VERSION "created by canmatrix"

NS_ :

BS_:

BU_: User ADM_PC_LL25 ADM_PC_BC25 ADM_PC_BP25 ADM_PC_BI25

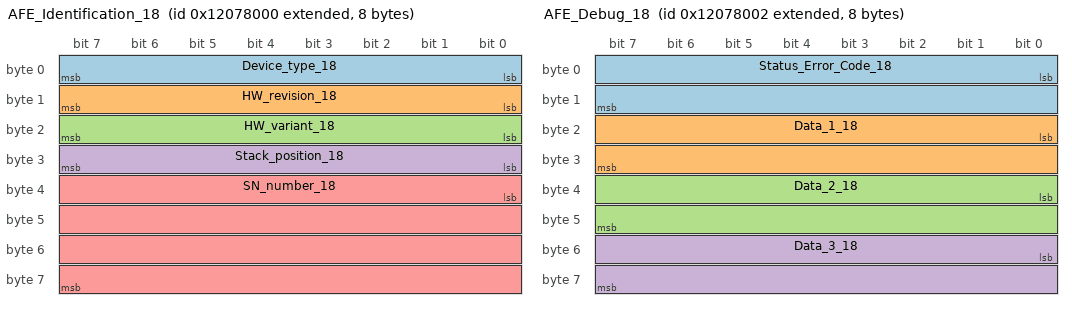
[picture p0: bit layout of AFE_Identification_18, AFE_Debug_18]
BO_ 2449965056 AFE_Identification_18: 8 ADM_PC_BP25
 SG_ Device_type_18 : 0|8@1+ (1,0) [0|255] "" Vector__XXX
 SG_ HW_revision_18 : 8|8@1+ (1,0) [0|255] "" Vector__XXX
 SG_ HW_variant_18 : 16|8@1+ (1,0) [0|255] "" Vector__XXX
 SG_ Stack_position_18 : 24|8@1+ (1,0) [0|255] "" Vector__XXX
 SG_ SN_number_18 : 32|32@1+ (1,0) [0|4294967295] "" Vector__XXX

BO_ 2449965057 AFE_FwInfo_18: 8 ADM_PC_BP25
 SG_ FW_info_mux_18 M : 56|8@1+ (1,0) [0|255] "" Vector__XXX
 SG_ FW_revision_0_18 m0 : 0|8@1+ (1,0) [0|255] "" Vector__XXX
 SG_ FW_revision_1_18 m0 : 8|8@1+ (1,0) [0|255] "" Vector__XXX
 SG_ FW_revision_2_18 m0 : 16|8@1+ (1,0) [0|255] "" Vector__XXX
 SG_ FW_revision_3_18 m0 : 24|8@1+ (1,0) [0|255] "" Vector__XXX
 SG_ FW_revision_4_18 m0 : 32|8@1+ (1,0) [0|255] "" Vector__XXX
 SG_ FW_revision_5_18 m0 : 40|8@1+ (1,0) [0|255] "" Vector__XXX
 SG_ FW_revision_6_18 m0 : 48|8@1+ (1,0) [0|255] "" Vector__XXX
 SG_ FW_revision_7_18 m1 : 0|8@1+ (1,0) [0|255] "" Vector__XXX
 SG_ FW_revision_8_18 m1 : 8|8@1+ (1,0) [0|255] "" Vector__XXX
 SG_ FW_revision_9_18 m1 : 16|8@1+ (1,0) [0|255] "" Vector__XXX
 SG_ FW_revision_10_18 m1 : 24|8@1+ (1,0) [0|255] "" Vector__XXX
 SG_ FW_revision_11_18 m1 : 32|8@1+ (1,0) [0|255] "" Vector__XXX
 SG_ FW_revision_12_18 m1 : 40|8@1+ (1,0) [0|255] "" Vector__XXX
 SG_ FW_revision_13_18 m1 : 48|8@1+ (1,0) [0|255] "" Vector__XXX
 SG_ FW_datecode_0_18 m2 : 0|8@1+ (1,0) [0|255] "" Vector__XXX
 SG_ FW_datecode_1_18 m2 : 8|8@1+ (1,0) [0|255] "" Vector__XXX
 SG_ FW_datecode_2_18 m2 : 16|8@1+ (1,0) [0|255] "" Vector__XXX
 SG_ FW_datecode_3_18 m2 : 24|8@1+ (1,0) [0|255] "" Vector__XXX
 SG_ FW_datecode_4_18 m2 : 32|8@1+ (1,0) [0|255] "" Vector__XXX
 SG_ FW_datecode_5_18 m2 : 40|8@1+ (1,0) [0|255] "" Vector__XXX
 SG_ FW_datecode_6_18 m2 : 48|8@1+ (1,0) [0|255] "" Vector__XXX
 SG_ FW_datecode_7_18 m3 : 0|8@1+ (1,0) [0|255] "" Vector__XXX
 SG_ FW_datecode_8_18 m3 : 8|8@1+ (1,0) [0|255] "" Vector__XXX
 SG_ FW_datecode_9_18 m3 : 16|8@1+ (1,0) [0|255] "" Vector__XXX
 SG_ FW_datecode_10_18 m3 : 24|8@1+ (1,0) [0|255] "" Vector__XXX
 SG_ FW_datecode_11_18 m3 : 32|8@1+ (1,0) [0|255] "" Vector__XXX
 SG_ FW_datecode_12_18 m3 : 40|8@1+ (1,0) [0|255] "" Vector__XXX
 SG_ FW_datecode_13_18 m3 : 48|8@1+ (1,0) [0|255] "" Vector__XXX

BO_ 2449965069 _AFE_Boot_FwInfo_18: 8 ADM_PC_BP25
 SG_ Boot_FW_info_mux_18 M : 56|8@1+ (1,0) [0|255] "" Vector__XXX
 SG_ FW_revision_0_18 m0 : 0|8@1+ (1,0) [0|255] "" Vector__XXX
 SG_ FW_revision_1_18 m0 : 8|8@1+ (1,0) [0|255] "" Vector__XXX
 SG_ FW_revision_2_18 m0 : 16|8@1+ (1,0) [0|255] "" Vector__XXX
 SG_ FW_revision_3_18 m0 : 24|8@1+ (1,0) [0|255] "" Vector__XXX
 SG_ FW_revision_4_18 m0 : 32|8@1+ (1,0) [0|255] "" Vector__XXX
 SG_ FW_revision_5_18 m0 : 40|8@1+ (1,0) [0|255] "" Vector__XXX
 SG_ FW_revision_6_18 m0 : 48|8@1+ (1,0) [0|255] "" Vector__XXX
 SG_ FW_revision_7_18 m1 : 0|8@1+ (1,0) [0|255] "" Vector__XXX
 SG_ FW_revision_8_18 m1 : 8|8@1+ (1,0) [0|255] "" Vector__XXX
 SG_ FW_revision_9_18 m1 : 16|8@1+ (1,0) [0|255] "" Vector__XXX
 SG_ FW_revision_10_18 m1 : 24|8@1+ (1,0) [0|255] "" Vector__XXX
 SG_ FW_revision_11_18 m1 : 32|8@1+ (1,0) [0|255] "" Vector__XXX
 SG_ FW_revision_12_18 m1 : 40|8@1+ (1,0) [0|255] "" Vector__XXX
 SG_ FW_revision_13_18 m1 : 48|8@1+ (1,0) [0|255] "" Vector__XXX
 SG_ FW_datecode_0_18 m2 : 0|8@1+ (1,0) [0|255] "" Vector__XXX
 SG_ FW_datecode_1_18 m2 : 8|8@1+ (1,0) [0|255] "" Vector__XXX
 SG_ FW_datecode_2_18 m2 : 16|8@1+ (1,0) [0|255] "" Vector__XXX
 SG_ FW_datecode_3_18 m2 : 24|8@1+ (1,0) [0|255] "" Vector__XXX
 SG_ FW_datecode_4_18 m2 : 32|8@1+ (1,0) [0|255] "" Vector__XXX
 SG_ FW_datecode_5_18 m2 : 40|8@1+ (1,0) [0|255] "" Vector__XXX
 SG_ FW_datecode_6_18 m2 : 48|8@1+ (1,0) [0|255] "" Vector__XXX
 SG_ FW_datecode_7_18 m3 : 0|8@1+ (1,0) [0|255] "" Vector__XXX
 SG_ FW_datecode_8_18 m3 : 8|8@1+ (1,0) [0|255] "" Vector__XXX
 SG_ FW_datecode_9_18 m3 : 16|8@1+ (1,0) [0|255] "" Vector__XXX
 SG_ FW_datecode_10_18 m3 : 24|8@1+ (1,0) [0|255] "" Vector__XXX
 SG_ FW_datecode_11_18 m3 : 32|8@1+ (1,0) [0|255] "" Vector__XXX
 SG_ FW_datecode_12_18 m3 : 40|8@1+ (1,0) [0|255] "" Vector__XXX
 SG_ FW_datecode_13_18 m3 : 48|8@1+ (1,0) [0|255] "" Vector__XXX

BO_ 2449965058 AFE_Debug_18: 8 ADM_PC_BP25
 SG_ Status_Error_Code_18 : 0|16@1+ (1,0) [0|65535] "" Vector__XXX
 SG_ Data_1_18 : 16|16@1+ (1,0) [0|65535] "" Vector__XXX
 SG_ Data_2_18 : 32|16@1+ (1,0) [0|65535] "" Vector__XXX
 SG_ Data_3_18 : 48|16@1+ (1,0) [0|65535] "" Vector__XXX

BO_ 2449965063 AFE_Status_18: 8 ADM_PC_BP25
 SG_ Running_18 : 0|1@1+ (1,0) [0|1] "" Vector__XXX
 SG_ PWM_18 : 1|1@1+ (1,0) [0|1] "" Vector__XXX
 SG_ Current_dc_loop_mode_18 : 2|1@1+ (1,0) [0|1] "" Vector__XXX
 SG_ Current_ac_loop_mode_18 : 3|1@1+ (1,0) [0|1] "" Vector__XXX
 SG_ Buck_18 : 5|1@1+ (1,0) [0|1] "" Vector__XXX
 SG_ Boost_18 : 6|1@1+ (1,0) [0|1] "" Vector__XXX
 SG_ Precharge_dc_buck_mode_18 : 7|1@1+ (1,0) [0|1] "" Vector__XXX
 SG_ Precharge_dc_boost_mode_18 : 8|1@1+ (1,0) [0|1] "" Vector__XXX
 SG_ Rectifier_3ph_18 : 9|1@1+ (1,0) [0|1] "" Vector__XXX
 SG_ Stack_mode_18 : 10|1@1+ (1,0) [0|1] "" Vector__XXX
 SG_ Master_18 : 11|1@1+ (1,0) [0|1] "" Vector__XXX
 SG_ Slave_18 : 12|1@1+ (1,0) [0|1] "" Vector__XXX
 SG_ Inverter_1ph_18 : 13|1@1+ (1,0) [0|1] "" Vector__XXX
 SG_ Boost_Neutral_18 : 14|1@1+ (1,0) [0|1] "" Vector__XXX
 SG_ Rectifier_1ph_18 : 15|1@1+ (1,0) [0|1] "" Vector__XXX
 SG_ Inverter_3ph_18 : 16|1@1+ (1,0) [0|1] "" Vector__XXX
 SG_ Ready_18 : 17|1@1+ (1,0) [0|1] "" Vector__XXX
 SG_ Inverter_1ph_Sync_18 : 18|1@1+ (1,0) [0|1] "" Vector__XXX
 SG_ Neutral_18 : 19|1@1+ (1,0) [0|1] "" Vector__XXX
 SG_ Rectifier_1ph_Buck_18 : 20|1@1+ (1,0) [0|1] "" Vector__XXX
 SG_ Inverter_1ph_Boost_18 : 21|1@1+ (1,0) [0|1] "" Vector__XXX
 SG_ Rectifier_distributed_18 : 22|1@1+ (1,0) [0|1] "" Vector__XXX
 SG_ MPPT_buck_18 : 23|1@1+ (1,0) [0|1] "" Vector__XXX
 SG_ MPPT_boost_18 : 24|1@1+ (1,0) [0|1] "" Vector__XXX
 SG_ Buck_2p_float_18 : 25|1@1+ (1,0) [0|1] "" Vector__XXX
 SG_ Inverter_1ph_Distributed_18 : 26|1@1+ (1,0) [0|1] "" Vector__XXX

BO_ 2449965062 AFE_Faults_18: 3 ADM_PC_BP25
 SG_ Protection_trip_internal_18 : 0|1@1+ (1,0) [0|1] "" Vector__XXX
 SG_ Protection_trip_external_18 : 1|1@1+ (1,0) [0|1] "" Vector__XXX
 SG_ Phase_U_overcurrent_18 : 2|1@1+ (1,0) [0|1] "" Vector__XXX
 SG_ Phase_U_overvoltage_18 : 3|1@1+ (1,0) [0|1] "" Vector__XXX
 SG_ Phase_U_undervoltage_18 : 4|1@1+ (1,0) [0|1] "" Vector__XXX
 SG_ Phase_V_overvoltage_18 : 5|1@1+ (1,0) [0|1] "" Vector__XXX
 SG_ Phase_V_undervoltage_18 : 6|1@1+ (1,0) [0|1] "" Vector__XXX
 SG_ Phase_V_overcurrent_18 : 7|1@1+ (1,0) [0|1] "" Vector__XXX
 SG_ Phase_W_overvoltage_18 : 8|1@1+ (1,0) [0|1] "" Vector__XXX
 SG_ Phase_W_undervoltage_18 : 9|1@1+ (1,0) [0|1] "" Vector__XXX
 SG_ Phase_W_overcurrent_18 : 10|1@1+ (1,0) [0|1] "" Vector__XXX
 SG_ DC_undervoltage_18 : 11|1@1+ (1,0) [0|1] "" Vector__XXX
 SG_ DC_overvoltage_18 : 12|1@1+ (1,0) [0|1] "" Vector__XXX
 SG_ MOSFET_overtemperature_18 : 13|1@1+ (1,0) [0|1] "" Vector__XXX
 SG_ Inductor_overtemperature_18 : 14|1@1+ (1,0) [0|1] "" Vector__XXX
 SG_ Keep_Alive_not_served_18 : 15|1@1+ (1,0) [0|1] "" Vector__XXX
 SG_ PLL_not_locked_18 : 16|1@1+ (1,0) [0|1] "" Vector__XXX
 SG_ NFO_18 : 20|1@1+ (1,0) [0|1] "" Vector__XXX
 SG_ Measurement_system_failure_18 : 21|1@1+ (1,0) [0|1] "" Vector__XXX
 SG_ EEPROM_failure_18 : 22|1@1+ (1,0) [0|1] "" Vector__XXX
 SG_ System_18 : 23|1@1+ (1,0) [0|1] "" Vector__XXX

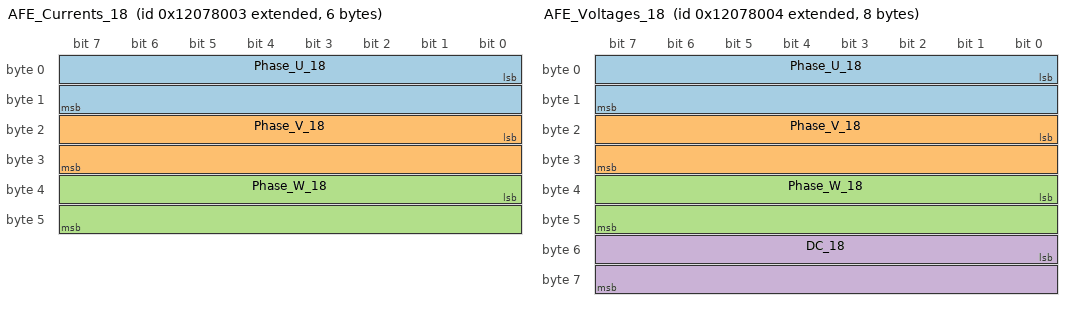
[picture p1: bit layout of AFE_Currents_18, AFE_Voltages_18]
BO_ 2449965059 AFE_Currents_18: 6 ADM_PC_BP25
 SG_ Phase_U_18 : 0|16@1- (0.01,0) [-327.68|327.67] "A" Vector__XXX
 SG_ Phase_V_18 : 16|16@1- (0.01,0) [-327.68|327.67] "A" Vector__XXX
 SG_ Phase_W_18 : 32|16@1- (0.01,0) [-327.68|327.67] "A" Vector__XXX

BO_ 2449965072 AFE_DC_Bus_current_18: 2 ADM_PC_BP25
 SG_ Bus_current_18 : 0|16@1- (0.01,0) [-327.68|327.67] "A" Vector__XXX

BO_ 2449965070 _AFE_Broadcast_18: 8 ADM_PC_BP25
 SG_ Diagnostics_Index_18 M : 56|8@1+ (1,0) [0|255] "" Vector__XXX
 SG_ Phase_U_18 m1 : 8|16@1- (0.01,0) [-327.68|327.67] "A" ADM_PC_BP25
 SG_ Phase_V_18 m1 : 24|16@1- (0.01,0) [-327.68|327.67] "A" ADM_PC_BP25
 SG_ Phase_W_18 m1 : 40|16@1- (0.01,0) [-327.68|327.67] "A" ADM_PC_BP25
 SG_ Stack_position_18 : 0|5@1+ (1,0) [0|31] "" ADM_PC_BP25
 SG_ Group_ID_18 : 5|3@1+ (1,0) [0|7] "" ADM_PC_BP25

BO_ 2449965060 AFE_Voltages_18: 8 ADM_PC_BP25
 SG_ Phase_U_18 : 0|16@1- (0.1,0) [-3276.8|3276.7] "V" Vector__XXX
 SG_ Phase_V_18 : 16|16@1- (0.1,0) [-3276.8|3276.7] "V" Vector__XXX
 SG_ Phase_W_18 : 32|16@1- (0.1,0) [-3276.8|3276.7] "V" Vector__XXX
 SG_ DC_18 : 48|16@1- (0.1,0) [-3276.8|3276.7] "V" Vector__XXX

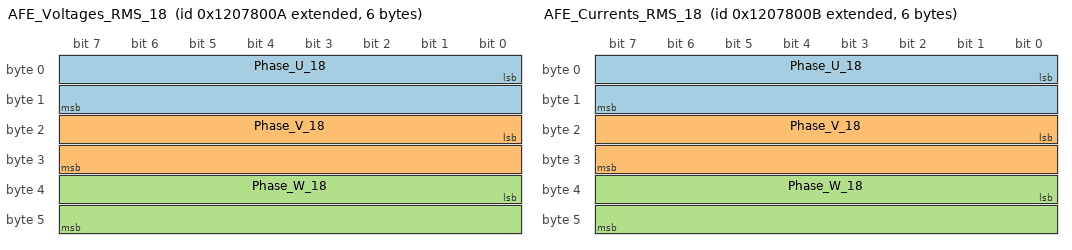
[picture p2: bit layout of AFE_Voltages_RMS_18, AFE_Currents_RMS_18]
BO_ 2449965066 AFE_Voltages_RMS_18: 6 ADM_PC_BP25
 SG_ Phase_U_18 : 0|16@1+ (0.1,0) [0|6553.5] "V" Vector__XXX
 SG_ Phase_V_18 : 16|16@1+ (0.1,0) [0|6553.5] "V" Vector__XXX
 SG_ Phase_W_18 : 32|16@1+ (0.1,0) [0|6553.5] "V" Vector__XXX

BO_ 2449965067 AFE_Currents_RMS_18: 6 ADM_PC_BP25
 SG_ Phase_U_18 : 0|16@1+ (0.01,0) [0.00|655.35] "A" Vector__XXX
 SG_ Phase_V_18 : 16|16@1+ (0.01,0) [0.00|655.35] "A" Vector__XXX
 SG_ Phase_W_18 : 32|16@1+ (0.01,0) [0.00|655.35] "A" Vector__XXX

BO_ 2449965068 AFE_Mains_18: 4 ADM_PC_BP25
 SG_ Frequency_18 : 0|16@1+ (0.01,0) [0.00|655.35] "Hz" Vector__XXX
 SG_ Phase_18 : 16|16@1- (0.1,0) [-3276.8|3276.7] "Deg." Vector__XXX

BO_ 2449965061 AFE_Temperatures_18: 4 ADM_PC_BP25
 SG_ Temp_Bridge_18 : 0|16@1- (0.01,0) [-327.68|327.67] "°C" Vector__XXX
 SG_ Temp_Inductors_18 : 16|16@1- (0.01,0) [-327.68|327.67] "°C" Vector__XXX

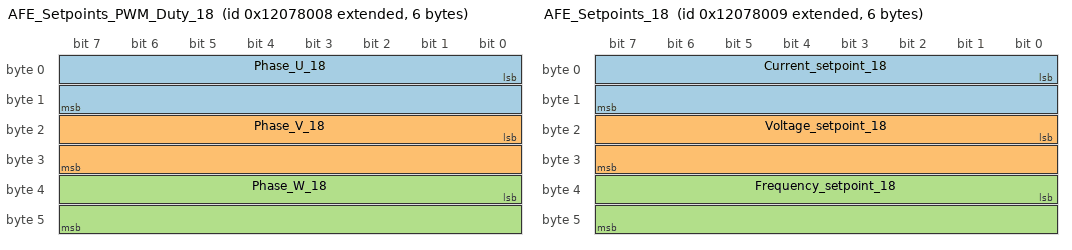
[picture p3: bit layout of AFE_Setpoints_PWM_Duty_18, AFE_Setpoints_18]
BO_ 2449965064 AFE_Setpoints_PWM_Duty_18: 6 ADM_PC_BP25
 SG_ Phase_U_18 : 0|16@1+ (0.001525902,0) [0E-009|99.999987570] "%" Vector__XXX
 SG_ Phase_V_18 : 16|16@1+ (0.001525902,0) [0E-009|99.999987570] "%" Vector__XXX
 SG_ Phase_W_18 : 32|16@1+ (0.001525902,0) [0E-009|99.999987570] "%" Vector__XXX

BO_ 2449965065 AFE_Setpoints_18: 6 ADM_PC_BP25
 SG_ Current_setpoint_18 : 0|16@1- (0.01,0) [-327.68|327.67] "A" Vector__XXX
 SG_ Voltage_setpoint_18 : 16|16@1+ (0.1,0) [0|6553.5] "V" Vector__XXX
 SG_ Frequency_setpoint_18 : 32|16@1+ (0.01,0) [0.00|655.35] "Hz" Vector__XXX

BO_ 2449932384 AFE_Keep_Alive_18: 1 User
 SG_ Keep_Alive_Enable_18 : 0|1@1+ (1,0) [0|1] "" ADM_PC_BP25

BO_ 2449932352 AFE_Mode_Control_18: 8 User
 SG_ Converter_ON_18 : 0|1@1+ (1,0) [0|1] "" ADM_PC_BP25
 SG_ PWM_ON_18 : 1|1@1+ (1,0) [0|1] "" ADM_PC_BP25
 SG_ DC_Current_feedback_ON_18 : 2|1@1+ (1,0) [0|1] "" ADM_PC_BP25
 SG_ AC_Current_feedback_ON_18 : 3|1@1+ (1,0) [0|1] "" ADM_PC_BP25
 SG_ Buck_ON_18 : 5|1@1+ (1,0) [0|1] "" ADM_PC_BP25
 SG_ Boost_ON_18 : 6|1@1+ (1,0) [0|1] "" ADM_PC_BP25
 SG_ Rectifier_3ph_ON_18 : 9|1@1+ (1,0) [0|1] "" ADM_PC_BP25
 SG_ Inverter_1ph_ON_18 : 10|1@1+ (1,0) [0|1] "" ADM_PC_BP25
 SG_ Rectifier_1ph_ON_18 : 11|1@1+ (1,0) [0|1] "" ADM_PC_BP25
 SG_ Boost_Neutral_ON_18 : 12|1@1+ (1,0) [0|1] "" ADM_PC_BP25
 SG_ Inverter_3ph_ON_18 : 13|1@1+ (1,0) [0|1] "" ADM_PC_BP25
 SG_ Inverter_1ph_Sync_ON_18 : 14|1@1+ (1,0) [0|1] "" ADM_PC_BP25
 SG_ Neutral_ON_18 : 15|1@1+ (1,0) [0|1] "" ADM_PC_BP25
 SG_ Rectifier_1ph_Buck_ON_18 : 16|1@1+ (1,0) [0|1] "" ADM_PC_BP25
 SG_ Inverter_1ph_Boost_ON_18 : 17|1@1+ (1,0) [0|1] "" ADM_PC_BP25
 SG_ Rectifier_Distributed_ON_18 : 18|1@1+ (1,0) [0|1] "" ADM_PC_BP25
 SG_ MPPT_buck_ON_18 : 19|1@1+ (1,0) [0|1] "" ADM_PC_BP25
 SG_ MPPT_boost_ON_18 : 20|1@1+ (1,0) [0|1] "" ADM_PC_BP25
 SG_ Buck_2p_float_ON_18 : 21|1@1+ (1,0) [0|1] "" ADM_PC_BP25
 SG_ Inverter_1ph_Distributed_ON_18 : 22|1@1+ (1,0) [0|1] "" ADM_PC_BP25

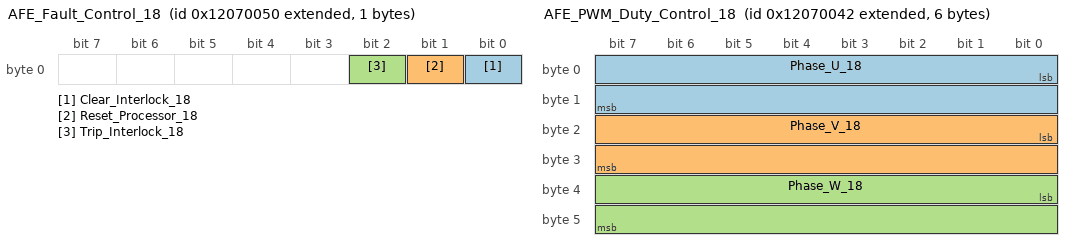
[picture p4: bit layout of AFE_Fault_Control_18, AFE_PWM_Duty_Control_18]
BO_ 2449932368 AFE_Fault_Control_18: 1 User
 SG_ Clear_Interlock_18 : 0|1@1+ (1,0) [0|1] "" ADM_PC_BP25
 SG_ Reset_Processor_18 : 1|1@1+ (1,0) [0|1] "" ADM_PC_BP25
 SG_ Trip_Interlock_18 : 2|1@1+ (1,0) [0|1] "" ADM_PC_BP25

BO_ 2449932353 AFE_Reactive_Current_Setpoint_Co: 2 User
 SG_ Reactive_current_setpoint_18 : 0|16@1- (0.01,0) [-150|150] "A" ADM_PC_BP25

BO_ 2449932354 AFE_PWM_Duty_Control_18: 6 User
 SG_ Phase_U_18 : 0|16@1+ (0.001525902,0) [0E-009|99.999987570] "%" ADM_PC_BP25
 SG_ Phase_V_18 : 16|16@1+ (0.001525902,0) [0E-009|99.999987570] "%" ADM_PC_BP25
 SG_ Phase_W_18 : 32|16@1+ (0.001525902,0) [0E-009|99.999987570] "%" ADM_PC_BP25

BO_ 2449932355 AFE_Current_Setpoint_Control_18: 2 User
 SG_ Current_setpoint_18 : 0|16@1- (0.01,0) [-150|150] "A" ADM_PC_BP25

BO_ 2449932356 AFE_Voltage_Setpoint_Control_18: 2 User
 SG_ Voltage_setpoint_18 : 0|16@1+ (0.1,0) [0|1500] "V" ADM_PC_BP25

BO_ 2449932360 AFE_Frequency_Setpoint_Control_1: 2 User
 SG_ Frequency_setpoint_18 : 0|16@1+ (0.01,0) [40|70] "Hz" ADM_PC_BP25

BO_ 2449932361 AFE_Phase_Setpoint_Control_18: 2 User
 SG_ Phase_setpoint_18 : 0|16@1+ (1,0) [0|360] "deg" ADM_PC_BP25

BO_ 2449932400 AFE_Rectifier_Setpoint_Control_1: 8 User
 SG_ Voltage_setpoint_2_18 : 0|16@1+ (0.1,0) [0|1500] "V" ADM_PC_BP25
 SG_ Current_setpoint_2_18 : 16|16@1- (0.01,0) [-150|150] "A" ADM_PC_BP25

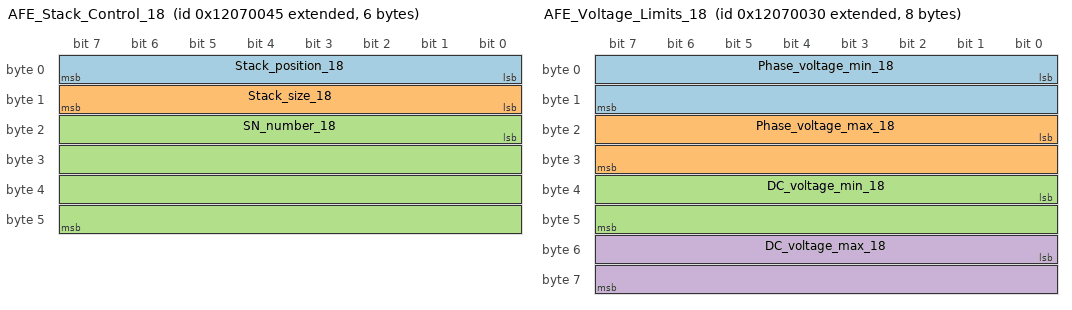
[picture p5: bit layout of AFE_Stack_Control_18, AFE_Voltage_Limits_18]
BO_ 2449932357 AFE_Stack_Control_18: 6 User
 SG_ Stack_position_18 : 0|8@1+ (1,0) [0|255] "" ADM_PC_BP25
 SG_ Stack_size_18 : 8|8@1+ (1,0) [0|255] "" ADM_PC_BP25
 SG_ SN_number_18 : 16|32@1+ (1,0) [0|4294967295] "" ADM_PC_BP25

BO_ 2449932336 AFE_Voltage_Limits_18: 8 User
 SG_ Phase_voltage_min_18 : 0|16@1- (0.1,0) [0|3276.7] "V" ADM_PC_BP25
 SG_ Phase_voltage_max_18 : 16|16@1- (0.1,0) [-3276.8|850] "V" ADM_PC_BP25
 SG_ DC_voltage_min_18 : 32|16@1- (0.1,0) [0|3276.7] "V" ADM_PC_BP25
 SG_ DC_voltage_max_18 : 48|16@1- (0.1,0) [-3276.8|850] "V" ADM_PC_BP25

BO_ 2449932337 AFE_Current_Limits_18: 4 User
 SG_ Phase_current_min_18 : 0|16@1- (0.01,0) [-60|60] "A" ADM_PC_BP25
 SG_ Phase_current_max_18 : 16|16@1- (0.01,0) [-60|60] "A" ADM_PC_BP25

BO_ 2449932364 AFE_Group_Control_18: 1 User
 SG_ Group_ID_18 : 0|8@1+ (1,0) [0|255] "" ADM_PC_BP25

BO_ 2449965071 AFE_Group_Info_18: 1 ADM_PC_BP25
 SG_ Group_ID_18 : 0|8@1+ (1,0) [0|255] "" Vector__XXX

BO_ 2449932385 AFE_System_Flags_Control_18: 8 User
 SG_ Factory_mode_18 : 0|1@1+ (1,0) [0|1] "" ADM_PC_BP25
 SG_ Silent_CAN_mode_18 : 1|1@1+ (1,0) [0|1] "" ADM_PC_BP25

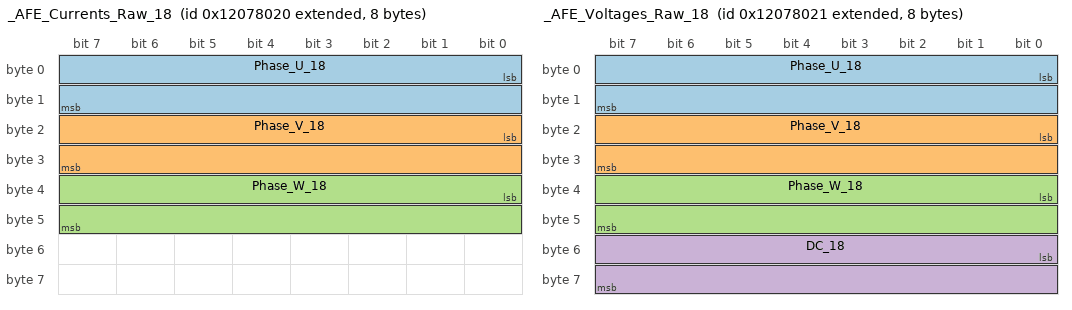
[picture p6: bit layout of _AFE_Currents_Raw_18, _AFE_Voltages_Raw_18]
BO_ 2449965088 _AFE_Currents_Raw_18: 8 ADM_PC_BP25
 SG_ Phase_U_18 : 0|16@1- (1,0) [-32768|32767] "" Vector__XXX
 SG_ Phase_V_18 : 16|16@1- (1,0) [-32768|32767] "" Vector__XXX
 SG_ Phase_W_18 : 32|16@1- (1,0) [-32768|32767] "" Vector__XXX

BO_ 2449965089 _AFE_Voltages_Raw_18: 8 ADM_PC_BP25
 SG_ Phase_U_18 : 0|16@1- (1,0) [-32768|32767] "" Vector__XXX
 SG_ Phase_V_18 : 16|16@1- (1,0) [-32768|32767] "" Vector__XXX
 SG_ Phase_W_18 : 32|16@1- (1,0) [-32768|32767] "" Vector__XXX
 SG_ DC_18 : 48|16@1- (1,0) [-32768|32767] "" Vector__XXX

BO_ 2449932362 _AFE_ADC_Calibration_Mode_18: 1 User
 SG_ Calibration_Index_18 M : 2|5@1+ (1,0) [0|31] "" Vector__XXX
 SG_ Current_U_18 m1 : 0|2@1+ (1,0) [0|3] "" ADM_PC_BP25
 SG_ Current_V_18 m2 : 0|2@1+ (1,0) [0|3] "" ADM_PC_BP25
 SG_ Current_W_18 m3 : 0|2@1+ (1,0) [0|3] "" ADM_PC_BP25
 SG_ Voltage_U_18 m4 : 0|2@1+ (1,0) [0|3] "" ADM_PC_BP25
 SG_ Voltage_V_18 m5 : 0|2@1+ (1,0) [0|3] "" ADM_PC_BP25
 SG_ Voltage_W_18 m6 : 0|2@1+ (1,0) [0|3] "" ADM_PC_BP25
 SG_ Voltage_DC_18 m7 : 0|2@1+ (1,0) [0|3] "" ADM_PC_BP25
 SG_ start_18 : 7|1@1+ (1,0) [0|1] "" ADM_PC_BP25

BO_ 2449932363 _AFE_ADC_Calibration_Setpoint_18: 3 User
 SG_ Calibration_Index_18 M : 16|5@1+ (1,0) [0|31] "" Vector__XXX
 SG_ Current_U_18 m1 : 0|16@1- (0.01,0) [-100|100] "A" ADM_PC_BP25
 SG_ Current_V_18 m2 : 0|16@1- (0.01,0) [-100|100] "A" ADM_PC_BP25
 SG_ Current_W_18 m3 : 0|16@1- (0.01,0) [-100|100] "A" ADM_PC_BP25
 SG_ Voltage_U_18 m4 : 0|16@1+ (0.1,0) [0|1500] "V" ADM_PC_BP25
 SG_ Voltage_V_18 m5 : 0|16@1+ (0.1,0) [0|1500] "V" ADM_PC_BP25
 SG_ Voltage_W_18 m6 : 0|16@1+ (0.1,0) [0|1500] "V" ADM_PC_BP25
 SG_ Voltage_DC_18 m7 : 0|16@1+ (0.1,0) [0|1500] "V" ADM_PC_BP25
 SG_ point_18 : 21|3@1+ (1,0) [0|7] "" ADM_PC_BP25

BO_ 2449932358 _AFE_Calibration_Offset_Update_1: 6 User
 SG_ Calibration_Index_18 M : 16|16@1+ (1,0) [0|65535] "" Vector__XXX
 SG_ Current_U_18 m0 : 0|16@1- (1,0) [-32768|32767] "ADC Counts" ADM_PC_BP25
 SG_ Current_V_18 m1 : 0|16@1- (1,0) [-32768|32767] "ADC Counts" ADM_PC_BP25
 SG_ Current_W_18 m2 : 0|16@1- (1,0) [-32768|32767] "ADC Counts" ADM_PC_BP25
 SG_ Voltage_U_18 m3 : 0|16@1- (1,0) [-32768|32767] "ADC Counts" ADM_PC_BP25
 SG_ Voltage_V_18 m4 : 0|16@1- (1,0) [-32768|32767] "ADC Counts" ADM_PC_BP25
 SG_ Voltage_W_18 m5 : 0|16@1- (1,0) [-32768|32767] "ADC Counts" ADM_PC_BP25
 SG_ Voltage_DC_18 m6 : 0|16@1- (1,0) [-32768|32767] "ADC Counts" ADM_PC_BP25
 SG_ CRC_18 : 32|16@1+ (1,0) [0|65535] "-" ADM_PC_BP25

BO_ 2449932359 _AFE_Calibration_Scale_Update_18: 6 User
 SG_ Calibration_Index_18 M : 16|16@1+ (1,0) [0|65535] "" Vector__XXX
 SG_ Current_U_18 m0 : 0|16@1- (0.0000152587890625,0) [-0.5000000000000000|0.4999847412109375] "scale = 1.0 + value" ADM_PC_BP25
 SG_ Current_V_18 m1 : 0|16@1- (0.0000152587890625,0) [-0.5000000000000000|0.4999847412109375] "scale = 1.0 + value" ADM_PC_BP25
 SG_ Current_W_18 m2 : 0|16@1- (0.0000152587890625,0) [-0.5000000000000000|0.4999847412109375] "scale = 1.0 + value" ADM_PC_BP25
 SG_ Voltage_U_18 m3 : 0|16@1- (0.0000152587890625,0) [-0.5000000000000000|0.4999847412109375] "scale = 1.0 + value" ADM_PC_BP25
 SG_ Voltage_V_18 m4 : 0|16@1- (0.0000152587890625,0) [-0.5000000000000000|0.4999847412109375] "scale = 1.0 + value" ADM_PC_BP25
 SG_ Voltage_W_18 m5 : 0|16@1- (0.0000152587890625,0) [-0.5000000000000000|0.4999847412109375] "scale = 1.0 + value" ADM_PC_BP25
 SG_ Voltage_DC_18 m6 : 0|16@1- (0.0000152587890625,0) [-0.5000000000000000|0.4999847412109375] "scale = 1.0 + value" ADM_PC_BP25
 SG_ CRC_18 : 32|16@1+ (1,0) [0|65535] "-" ADM_PC_BP25

BO_ 2449965137 _AFE_Calibration_Adc_Scale_18: 6 ADM_PC_BP25
 SG_ Adc_Index_18 M : 32|16@1+ (1,0) [0|65535] "" Vector__XXX
 SG_ Current_U_18 m0 : 0|32@1+ (1,0) [0|4294967295] "1 / adc_bins" User
 SG_ Current_V_18 m1 : 0|32@1+ (1,0) [0|4294967295] "1 / adc_bins" User
 SG_ Current_W_18 m2 : 0|32@1+ (1,0) [0|4294967295] "1 / adc_bins" User
 SG_ Voltage_U_18 m3 : 0|32@1+ (1,0) [0|4294967295] "1 / adc_bins" User
 SG_ Voltage_V_18 m4 : 0|32@1+ (1,0) [0|4294967295] "1 / adc_bins" User
 SG_ Voltage_W_18 m5 : 0|32@1+ (1,0) [0|4294967295] "1 / adc_bins" User
 SG_ Voltage_DC_18 m6 : 0|32@1+ (1,0) [0|4294967295] "1 / adc_bins" User

BO_ 2449965138 _AFE_Calibration_Adc_Fs_18: 6 ADM_PC_BP25
 SG_ Adc_Index_18 M : 32|16@1+ (1,0) [0|65535] "" Vector__XXX
 SG_ Current_U_18 m0 : 0|32@1+ (1,0) [0|4294967295] "Fullscale" User
 SG_ Current_V_18 m1 : 0|32@1+ (1,0) [0|4294967295] "Fullscale" User
 SG_ Current_W_18 m2 : 0|32@1+ (1,0) [0|4294967295] "Fullscale" User
 SG_ Voltage_U_18 m3 : 0|32@1+ (1,0) [0|4294967295] "Fullscale" User
 SG_ Voltage_V_18 m4 : 0|32@1+ (1,0) [0|4294967295] "Fullscale" User
 SG_ Voltage_W_18 m5 : 0|32@1+ (1,0) [0|4294967295] "Fullscale" User
 SG_ Voltage_DC_18 m6 : 0|32@1+ (1,0) [0|4294967295] "Fullscale" User

BO_ 2449965139 _AFE_Calibration_Adc_Offset_18: 4 ADM_PC_BP25
 SG_ Adc_Index_18 M : 16|16@1+ (1,0) [0|65535] "" Vector__XXX
 SG_ Current_U_18 m0 : 0|16@1- (1,0) [-32768|32767] "-" User
 SG_ Current_V_18 m1 : 0|16@1- (1,0) [-32768|32767] "-" User
 SG_ Current_W_18 m2 : 0|16@1- (1,0) [-32768|32767] "-" User
 SG_ Voltage_U_18 m3 : 0|16@1- (1,0) [-32768|32767] "-" User
 SG_ Voltage_V_18 m4 : 0|16@1- (1,0) [-32768|32767] "-" User
 SG_ Voltage_W_18 m5 : 0|16@1- (1,0) [-32768|32767] "-" User
 SG_ Voltage_DC_18 m6 : 0|16@1- (1,0) [-32768|32767] "-" User

BO_ 2449965140 _AFE_Calibration_Adc_Gain_18: 4 ADM_PC_BP25
 SG_ Adc_Index_18 M : 16|16@1+ (1,0) [0|65535] "" Vector__XXX
 SG_ Current_U_18 m0 : 0|16@1- (1,0) [-32768|32767] "-" User
 SG_ Current_V_18 m1 : 0|16@1- (1,0) [-32768|32767] "-" User
 SG_ Current_W_18 m2 : 0|16@1- (1,0) [-32768|32767] "-" User
 SG_ Voltage_U_18 m3 : 0|16@1- (1,0) [-32768|32767] "-" User
 SG_ Voltage_V_18 m4 : 0|16@1- (1,0) [-32768|32767] "-" User
 SG_ Voltage_W_18 m5 : 0|16@1- (1,0) [-32768|32767] "-" User
 SG_ Voltage_DC_18 m6 : 0|16@1- (1,0) [-32768|32767] "-" User

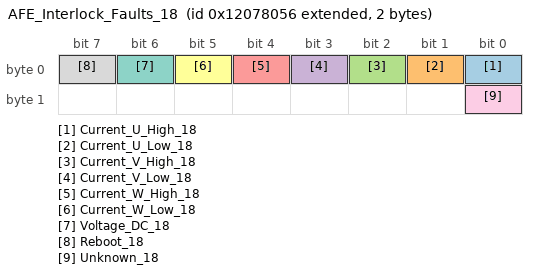
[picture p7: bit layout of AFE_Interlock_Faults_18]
BO_ 2449965142 AFE_Interlock_Faults_18: 2 ADM_PC_BP25
 SG_ Current_U_High_18 : 0|1@1+ (1,0) [0|1] "" Vector__XXX
 SG_ Current_U_Low_18 : 1|1@1+ (1,0) [0|1] "" Vector__XXX
 SG_ Current_V_High_18 : 2|1@1+ (1,0) [0|1] "" Vector__XXX
 SG_ Current_V_Low_18 : 3|1@1+ (1,0) [0|1] "" Vector__XXX
 SG_ Current_W_High_18 : 4|1@1+ (1,0) [0|1] "" Vector__XXX
 SG_ Current_W_Low_18 : 5|1@1+ (1,0) [0|1] "" Vector__XXX
 SG_ Voltage_DC_18 : 6|1@1+ (1,0) [0|1] "" Vector__XXX
 SG_ Reboot_18 : 7|1@1+ (1,0) [0|1] "" Vector__XXX
 SG_ Unknown_18 : 8|1@1+ (1,0) [0|1] "" Vector__XXX

BO_TX_BU_ 2449932352 : User,ADM_PC_LL25,ADM_PC_BC25,ADM_PC_BI25;
BO_TX_BU_ 2449932355 : User,ADM_PC_LL25,ADM_PC_BC25,ADM_PC_BI25;
BO_TX_BU_ 2449932356 : User,ADM_PC_LL25,ADM_PC_BC25,ADM_PC_BI25;
CM_ BO_ 2449965056  "Identification of the device";
CM_ BO_ 2449965057  "Git revision of the DSP firmware";
CM_ BO_ 2449965069  "Git revision of the bootloader firmware.";
CM_ BO_ 2449965058  "Values for debugging of HW/SW problems";
CM_ BO_ 2449965063  "Status bitfield";
CM_ BO_ 2449965062  "Fault bitfield";
CM_ BO_ 2449965059  "Current of phases U, V, W";
CM_ BO_ 2449965072  "Current of of the DC Bus";
CM_ BO_ 2449965070  "All AFEs will listen to this message";
CM_ BO_ 2449965067  "RMS Current of phases U, V, W";
CM_ BO_ 2449965068  "Three-Phase mains health (frequency, phase...)";
CM_ BO_ 2449965061  "Readouts of the module temperature sensors";
CM_ BO_ 2449965064  "Setpoints";
CM_ BO_ 2449965065  "Setpoints";
CM_ BO_ 2449932384  "Keep alive ping message. ";
CM_ BO_ 2449932352  "Operation Mode control: sets the converter operation mode";
CM_ BO_ 2449932368  "Fault Control: actions to clear faults and reset the system";
CM_ BO_ 2449932353  "Reactive power setpoint control.";
CM_ BO_ 2449932354  "PWM duty cycle control";
CM_ BO_ 2449932355  "Current setpoint control";
CM_ BO_ 2449932356  "Voltage setpoint control";
CM_ BO_ 2449932360  "Frequency setpoint control";
CM_ BO_ 2449932361  "Phase setpoint control";
CM_ BO_ 2449932400  "Additional voltage and current setpoints in single-phase rectifier and inverter control modes.";
CM_ BO_ 2449932357  "PFC stack control";
CM_ BO_ 2449932336  "Set the input and output voltage limits (minimum and maximum)";
CM_ BO_ 2449932337  "Set the output current limits (mminimum and maximum)";
CM_ BO_ 2449932364  "Set the Group ID of the device";
CM_ BO_ 2449965071  "Contains the Group ID of the device";
CM_ BO_ 2449932385  "Control the system flags";
CM_ BO_ 2449965088  "Current of phases A and B";
CM_ BO_ 2449965089  "Current of phases A and B";
CM_ BO_ 2449932362  "Automatic ADC calibration.";
CM_ BO_ 2449932363  "Setpoint for automatic ADC calibration.";
CM_ BO_ 2449932358  "Update of the calibration table for offsets.";
CM_ BO_ 2449932359  "Update of the calibration table for scales.";
CM_ BO_ 2449965137  "
                Adc scale (resolution) value of readouts.
            ";
CM_ BO_ 2449965138  "
                Adc fullscale value of readouts.
            ";
CM_ BO_ 2449965139  "
                Readout of ADC calibration data (offset) from EEPROM.
            ";
CM_ BO_ 2449965140  "
                Readout of ADC calibration data (gain) from EEPROM.
            ";
CM_ BO_ 2449965142  "Fault bitfield";

CM_ SG_ 2449965056 Device_type_18 "The device identification field, uniquely identifies the sender in the network";
CM_ SG_ 2449965056 HW_revision_18 "The hardware revision number";
CM_ SG_ 2449965056 HW_variant_18 "The DSP firmware revision number";
CM_ SG_ 2449965056 Stack_position_18 "Position of the module within the stack";
CM_ SG_ 2449965056 SN_number_18 "Unique module serial number";
CM_ SG_ 2449965057 FW_revision_0_18 "Character 0";
CM_ SG_ 2449965057 FW_revision_1_18 "Character 1";
CM_ SG_ 2449965057 FW_revision_2_18 "Character 2";
CM_ SG_ 2449965057 FW_revision_3_18 "Character 3";
CM_ SG_ 2449965057 FW_revision_4_18 "Character 3";
CM_ SG_ 2449965057 FW_revision_5_18 "Character 3";
CM_ SG_ 2449965057 FW_revision_6_18 "Character 3";
CM_ SG_ 2449965057 FW_revision_7_18 "Character 7";
CM_ SG_ 2449965057 FW_revision_8_18 "Character 8";
CM_ SG_ 2449965057 FW_revision_9_18 "Character 9";
CM_ SG_ 2449965057 FW_revision_10_18 "Character 10";
CM_ SG_ 2449965057 FW_revision_11_18 "Character 11";
CM_ SG_ 2449965057 FW_revision_12_18 "Character 12";
CM_ SG_ 2449965057 FW_revision_13_18 "Character 13";
CM_ SG_ 2449965057 FW_datecode_0_18 "Character 0";
CM_ SG_ 2449965057 FW_datecode_1_18 "Character 1";
CM_ SG_ 2449965057 FW_datecode_2_18 "Character 2";
CM_ SG_ 2449965057 FW_datecode_3_18 "Character 3";
CM_ SG_ 2449965057 FW_datecode_4_18 "Character 3";
CM_ SG_ 2449965057 FW_datecode_5_18 "Character 3";
CM_ SG_ 2449965057 FW_datecode_6_18 "Character 3";
CM_ SG_ 2449965057 FW_datecode_7_18 "Character 7";
CM_ SG_ 2449965057 FW_datecode_8_18 "Character 8";
CM_ SG_ 2449965057 FW_datecode_9_18 "Character 9";
CM_ SG_ 2449965057 FW_datecode_10_18 "Character 10";
CM_ SG_ 2449965057 FW_datecode_11_18 "Character 11";
CM_ SG_ 2449965057 FW_datecode_12_18 "Character 12";
CM_ SG_ 2449965057 FW_datecode_13_18 "Character 13";
CM_ SG_ 2449965069 FW_revision_0_18 "Character 0";
CM_ SG_ 2449965069 FW_revision_1_18 "Character 1";
CM_ SG_ 2449965069 FW_revision_2_18 "Character 2";
CM_ SG_ 2449965069 FW_revision_3_18 "Character 3";
CM_ SG_ 2449965069 FW_revision_4_18 "Character 3";
CM_ SG_ 2449965069 FW_revision_5_18 "Character 3";
CM_ SG_ 2449965069 FW_revision_6_18 "Character 3";
CM_ SG_ 2449965069 FW_revision_7_18 "Character 7";
CM_ SG_ 2449965069 FW_revision_8_18 "Character 8";
CM_ SG_ 2449965069 FW_revision_9_18 "Character 9";
CM_ SG_ 2449965069 FW_revision_10_18 "Character 10";
CM_ SG_ 2449965069 FW_revision_11_18 "Character 11";
CM_ SG_ 2449965069 FW_revision_12_18 "Character 12";
CM_ SG_ 2449965069 FW_revision_13_18 "Character 13";
CM_ SG_ 2449965069 FW_datecode_0_18 "Character 0";
CM_ SG_ 2449965069 FW_datecode_1_18 "Character 1";
CM_ SG_ 2449965069 FW_datecode_2_18 "Character 2";
CM_ SG_ 2449965069 FW_datecode_3_18 "Character 3";
CM_ SG_ 2449965069 FW_datecode_4_18 "Character 3";
CM_ SG_ 2449965069 FW_datecode_5_18 "Character 3";
CM_ SG_ 2449965069 FW_datecode_6_18 "Character 3";
CM_ SG_ 2449965069 FW_datecode_7_18 "Character 7";
CM_ SG_ 2449965069 FW_datecode_8_18 "Character 8";
CM_ SG_ 2449965069 FW_datecode_9_18 "Character 9";
CM_ SG_ 2449965069 FW_datecode_10_18 "Character 10";
CM_ SG_ 2449965069 FW_datecode_11_18 "Character 11";
CM_ SG_ 2449965069 FW_datecode_12_18 "Character 12";
CM_ SG_ 2449965069 FW_datecode_13_18 "Character 13";
CM_ SG_ 2449965058 Status_Error_Code_18 "Main status / error code as defined in errno/errno.h";
CM_ SG_ 2449965058 Data_1_18 "Additional information for the error/status";
CM_ SG_ 2449965058 Data_2_18 "Additional information for the error/status";
CM_ SG_ 2449965058 Data_3_18 "Additional information for the error/status";
CM_ SG_ 2449965063 Running_18 "Indicates if converter is running.";
CM_ SG_ 2449965063 PWM_18 "Indicates if converter is in PWM control mode.";
CM_ SG_ 2449965063 Current_dc_loop_mode_18 "Indicates if the current DC loop is enabled.";
CM_ SG_ 2449965063 Current_ac_loop_mode_18 "Indicates if the current AC loop is enabled.";
CM_ SG_ 2449965063 Buck_18 "Indicates if converter is in buck control mode.";
CM_ SG_ 2449965063 Boost_18 "Indicates if converter is in boost control mode.";
CM_ SG_ 2449965063 Precharge_dc_buck_mode_18 "Indicates if the precharge DC mode is enabled - buck direction.";
CM_ SG_ 2449965063 Precharge_dc_boost_mode_18 "Indicates if the precharge DC mode is enabled - boost direction.";
CM_ SG_ 2449965063 Rectifier_3ph_18 "Indicates if converter is in three-phase rectifier control mode.";
CM_ SG_ 2449965063 Stack_mode_18 "Indicates if converter is operating in stack mode.";
CM_ SG_ 2449965063 Master_18 "Indicates if converter is master in the stack.";
CM_ SG_ 2449965063 Slave_18 "Indicates if converter is slave in the stack.";
CM_ SG_ 2449965063 Inverter_1ph_18 "Indicates if converter is in single-phase inverter control mode.";
CM_ SG_ 2449965063 Boost_Neutral_18 "Indicates if converter is in boost control mode with neutral generation.";
CM_ SG_ 2449965063 Rectifier_1ph_18 "Indicates if converter is in single-phase rectifier control mode.";
CM_ SG_ 2449965063 Inverter_3ph_18 "Indicates if converter is in three-phase inverter control mode.";
CM_ SG_ 2449965063 Ready_18 "Indicates if converter is ready for operation.";
CM_ SG_ 2449965063 Inverter_1ph_Sync_18 "Single-phase inverter control mode with phase synchronization.";
CM_ SG_ 2449965063 Neutral_18 "Open-loop neutral generation.";
CM_ SG_ 2449965063 Rectifier_1ph_Buck_18 "Single-phase rectifier with buck on one leg.";
CM_ SG_ 2449965063 Inverter_1ph_Boost_18 "Single-phase inverter with boost on one leg.";
CM_ SG_ 2449965063 Rectifier_distributed_18 "Not available at the moment";
CM_ SG_ 2449965063 MPPT_buck_18 "Not available at the moment";
CM_ SG_ 2449965063 MPPT_boost_18 "Not available at the moment";
CM_ SG_ 2449965063 Buck_2p_float_18 "Buck in phases L1 and L2. Phase L3 is left floating (high impedance)";
CM_ SG_ 2449965063 Inverter_1ph_Distributed_18 "Single-phase inverter mode  distributed";
CM_ SG_ 2449965062 Protection_trip_internal_18 "This flagg is asserted if the interlock is open due to an internal fault condition (self-protection)";
CM_ SG_ 2449965062 Protection_trip_external_18 "This flag is asserted if the interlock is open due to an external condition received in the module.";
CM_ SG_ 2449965062 Phase_U_overcurrent_18 "Indicates an overcurrent event on Phase U. The overcurrent event is triggered when the measured phase current is over the programmed current limit.";
CM_ SG_ 2449965062 Phase_U_overvoltage_18 "Indicates an overvoltage event on Phase U. The overvoltage event is triggered when the measured phase voltage is over the programmed voltage limit.";
CM_ SG_ 2449965062 Phase_U_undervoltage_18 "Indicates an undervoltage event on Phase U. The overvoltage event is triggered when the measured phase voltage is over the programmed voltage limit.";
CM_ SG_ 2449965062 Phase_V_overvoltage_18 "Indicates an overvoltage event on Phase V. The overvoltage event is triggered when the measured phase voltage is over the programmed voltage limit.";
CM_ SG_ 2449965062 Phase_V_undervoltage_18 "Indicates an undervoltage event on Phase U. The overvoltage event is triggered when the measured phase voltage is over the programmed voltage limit.";
CM_ SG_ 2449965062 Phase_V_overcurrent_18 "Indicates an overcurrent event on Phase U. The overcurrent event is triggered when the measured phase current is over the programmed current limit.";
CM_ SG_ 2449965062 Phase_W_overvoltage_18 "Indicates an overvoltage event on Phase U. The overvoltage event is triggered when the measured phase voltage is over the programmed voltage limit.";
CM_ SG_ 2449965062 Phase_W_undervoltage_18 "Indicates an undervoltage event on Phase U. The overvoltage event is triggered when the measured phase voltage is over the programmed voltage limit.";
CM_ SG_ 2449965062 Phase_W_overcurrent_18 "Indicates an overcurrent event on Phase U. The overcurrent event is triggered when the measured phase current is over the programmed current limit.";
CM_ SG_ 2449965062 DC_undervoltage_18 "DC bus undervoltage condition. The undervoltage condition is asserted when the measured dc bus voltage is under the programmed voltage limit.";
CM_ SG_ 2449965062 DC_overvoltage_18 "DC bus overvoltage condition. The overvoltage condition is asserted when the measured dc bus voltage is over the programmed voltage limit.";
CM_ SG_ 2449965062 MOSFET_overtemperature_18 "This flag is asserted when the temperature of the MOSFET block is too high.";
CM_ SG_ 2449965062 Inductor_overtemperature_18 "This flag is asserted when the temperature of the inductor block is too high.";
CM_ SG_ 2449965062 Keep_Alive_not_served_18 "The Keep Alive feature is enabled but it was not served with the periodic message.";
CM_ SG_ 2449965062 PLL_not_locked_18 "Flag asserted when in rectifier modes, the PLL went out of lock condition";
CM_ SG_ 2449965062 Measurement_system_failure_18 "The voltages/currents measurement system is malfunctionning, and readouts are not guaranteed to be accurate.";
CM_ SG_ 2449965062 EEPROM_failure_18 "The configuration EEPROM failed to load or save the module configuration.";
CM_ SG_ 2449965059 Phase_U_18 "Phase current is the MOSFET loop current, in the branch U of the converter.";
CM_ SG_ 2449965059 Phase_V_18 "Phase current is the MOSFET loop current, in the branch V of the converter.";
CM_ SG_ 2449965059 Phase_W_18 "Phase current is the MOSFET loop current, in the branch W of the converter.";
CM_ SG_ 2449965072 Bus_current_18 "DC Bus current is possitive when current goes from input to output";
CM_ SG_ 2449965070 Phase_U_18 "Phase current is the MOSFET loop current, in the branch U of the converter.";
CM_ SG_ 2449965070 Phase_V_18 "Phase current is the MOSFET loop current, in the branch V of the converter.";
CM_ SG_ 2449965070 Phase_W_18 "Phase current is the MOSFET loop current, in the branch W of the converter.";
CM_ SG_ 2449965070 Stack_position_18 "Sender Stack position";
CM_ SG_ 2449965070 Group_ID_18 "Sender Group ID";
CM_ SG_ 2449965067 Phase_U_18 "RMS Phase current is the MOSFET loop current, in the branch U of the converter.";
CM_ SG_ 2449965067 Phase_V_18 "RMS Phase current is the MOSFET loop current, in the branch V of the converter.";
CM_ SG_ 2449965067 Phase_W_18 "RMS Phase current is the MOSFET loop current, in the branch W of the converter.";
CM_ SG_ 2449965068 Frequency_18 "Frequency of Three-Phase system";
CM_ SG_ 2449965068 Phase_18 "Phase of Three-Phase system";
CM_ SG_ 2449965061 Temp_Bridge_18 "Temperature of the MOSFET block";
CM_ SG_ 2449965061 Temp_Inductors_18 "Temperature of the inductors";
CM_ SG_ 2449965064 Phase_U_18 "The actual PWM duty cycle setpoint";
CM_ SG_ 2449965064 Phase_V_18 "The actual PWM duty cycle setpoint";
CM_ SG_ 2449965064 Phase_W_18 "The actual PWM duty cycle setpoint";
CM_ SG_ 2449965065 Current_setpoint_18 "The actual current setpoint";
CM_ SG_ 2449965065 Voltage_setpoint_18 "The actual voltage setpoint";
CM_ SG_ 2449965065 Frequency_setpoint_18 "The actual frequency setpoint";
CM_ SG_ 2449932384 Keep_Alive_Enable_18 "If set to 1, module will expect to receive this message every second repeatedly, or it will stop operation";
CM_ SG_ 2449932352 Converter_ON_18 "Enable the converter.";
CM_ SG_ 2449932352 PWM_ON_18 "Enable the PWM control mode.";
CM_ SG_ 2449932352 DC_Current_feedback_ON_18 "Enable the DC current loop";
CM_ SG_ 2449932352 AC_Current_feedback_ON_18 "Enable the AC current loop";
CM_ SG_ 2449932352 Buck_ON_18 "Enable the buck control mode.";
CM_ SG_ 2449932352 Boost_ON_18 "Enable the boost control mode.";
CM_ SG_ 2449932352 Rectifier_3ph_ON_18 "Enable the three-phase rectifier control mode.";
CM_ SG_ 2449932352 Inverter_1ph_ON_18 "Enable the single-phase inverter control mode.";
CM_ SG_ 2449932352 Rectifier_1ph_ON_18 "Enable the single-phase rectifier control mode.";
CM_ SG_ 2449932352 Boost_Neutral_ON_18 "Enable the boost control mode with neutral generation.";
CM_ SG_ 2449932352 Inverter_3ph_ON_18 "Enable the three-phase inverter control mode.";
CM_ SG_ 2449932352 Inverter_1ph_Sync_ON_18 "Single-phase inverter control mode with phase synchronization.";
CM_ SG_ 2449932352 Neutral_ON_18 "Open-loop neutral generation.";
CM_ SG_ 2449932352 Rectifier_1ph_Buck_ON_18 "Single-phase rectifier with buck on one leg.";
CM_ SG_ 2449932352 Inverter_1ph_Boost_ON_18 "Single-phase inverter with boost on one leg.";
CM_ SG_ 2449932352 Rectifier_Distributed_ON_18 "Single-phase (floating) distributed rectifier";
CM_ SG_ 2449932352 MPPT_buck_ON_18 "MPPT buck";
CM_ SG_ 2449932352 MPPT_boost_ON_18 "MPPT boost";
CM_ SG_ 2449932352 Buck_2p_float_ON_18 "Boost on L1 and L2. Floating L3 (high-impedance)";
CM_ SG_ 2449932352 Inverter_1ph_Distributed_ON_18 "Single-phase inverter mode distributed";
CM_ SG_ 2449932368 Clear_Interlock_18 "Clears the converter interlock";
CM_ SG_ 2449932368 Reset_Processor_18 "Reset the converter DSP";
CM_ SG_ 2449932368 Trip_Interlock_18 "Trip the inetrnal Interlock";
CM_ SG_ 2449932353 Reactive_current_setpoint_18 "This defines reactive current setpoint for 3-phase rectifier mode";
CM_ SG_ 2449932354 Phase_U_18 "The actual PWM duty cycle setpoint";
CM_ SG_ 2449932354 Phase_V_18 "The actual PWM duty cycle setpoint";
CM_ SG_ 2449932354 Phase_W_18 "The actual PWM duty cycle setpoint";
CM_ SG_ 2449932355 Current_setpoint_18 "Sets the output current setpoint. Active only when the current loop is enabled";
CM_ SG_ 2449932356 Voltage_setpoint_18 "Sets the output voltage setpoint. Active only when the voltage loop is enabled";
CM_ SG_ 2449932360 Frequency_setpoint_18 "Sets the frequency for single-phase and three-phase generator modes.";
CM_ SG_ 2449932361 Phase_setpoint_18 "Sets the phase for inverter control modes.";
CM_ SG_ 2449932357 Stack_position_18 "The converter position within the stack";
CM_ SG_ 2449932357 Stack_size_18 "How many PFC converters are in stack in total";
CM_ SG_ 2449932357 SN_number_18 "Unique module serial number";
CM_ SG_ 2449932336 Phase_voltage_min_18 "Minimum tolerated phase voltage";
CM_ SG_ 2449932336 Phase_voltage_max_18 "Maximum allowable phase voltage";
CM_ SG_ 2449932336 DC_voltage_min_18 "Minimum allowable dc voltage";
CM_ SG_ 2449932336 DC_voltage_max_18 "Maximum allowable dc voltage";
CM_ SG_ 2449932337 Phase_current_min_18 "Minimum allowable output current";
CM_ SG_ 2449932337 Phase_current_max_18 "Maximum allowable output current";
CM_ SG_ 2449932364 Group_ID_18 "Desired group ID for the device";
CM_ SG_ 2449965071 Group_ID_18 "Group ID of the device";
CM_ SG_ 2449932385 Factory_mode_18 "Customers MUST NOT USE this bit. If set to 1, module will enter in factory mode. ";
CM_ SG_ 2449932385 Silent_CAN_mode_18 "Customers MUST NOT USE this bit. If set to 1, module will enter in factory mode. ";
CM_ SG_ 2449932362 start_18 "Start automatic calibration. Multiplexer index must be 0!";
CM_ SG_ 2449932363 point_18 "Calibration point index.";
CM_ SG_ 2449932358 CRC_18 "Checksum of bytes 0 to 3, CRC-CCITT, corresponding to qChecksum (www.qt.io)";
CM_ SG_ 2449932359 CRC_18 "Checksum of bytes 0 to 3, CRC-CCITT, corresponding to qChecksum (www.qt.io)";
CM_ SG_ 2449965142 Current_U_High_18 "This flag is set if a hight current on U tripped the internal interlock";
CM_ SG_ 2449965142 Current_U_Low_18 "This flag is set if a low current on U tripped the internal interlock";
CM_ SG_ 2449965142 Current_V_High_18 "This flag is set if a hight current on V tripped the internal interlock";
CM_ SG_ 2449965142 Current_V_Low_18 "This flag is set if a low current on V tripped the internal interlock";
CM_ SG_ 2449965142 Current_W_High_18 "This flag is set if a hight current on W tripped the internal interlock";
CM_ SG_ 2449965142 Current_W_Low_18 "This flag is set if a low current on W tripped the internal interlock";
CM_ SG_ 2449965142 Voltage_DC_18 "This flag is set if a voltage on DC tripped the internal interlock";
CM_ SG_ 2449965142 Reboot_18 "This flag is set if a reboot tripped the internal interlock";
CM_ SG_ 2449965142 Unknown_18 "This flag the reason for the internal interlock is unknown";

BA_DEF_ BO_ "SystemMessageLongSymbol" STRING;

BA_ "SystemMessageLongSymbol" BO_ 2449932353 "AFE_Reactive_Current_Setpoint_Control_18";
BA_ "SystemMessageLongSymbol" BO_ 2449932360 "AFE_Frequency_Setpoint_Control_18";
BA_ "SystemMessageLongSymbol" BO_ 2449932400 "AFE_Rectifier_Setpoint_Control_18";
BA_ "SystemMessageLongSymbol" BO_ 2449932358 "_AFE_Calibration_Offset_Update_18";

VAL_ 2449965056 Device_type_18 7 "AFE";
VAL_ 2449965062 Protection_trip_internal_18 1 "fault";
VAL_ 2449965062 Protection_trip_external_18 1 "fault";
VAL_ 2449965062 Phase_U_overcurrent_18 1 "fault";
VAL_ 2449965062 Phase_U_overvoltage_18 1 "fault";
VAL_ 2449965062 Phase_U_undervoltage_18 1 "fault";
VAL_ 2449965062 Phase_V_overvoltage_18 1 "fault";
VAL_ 2449965062 Phase_V_undervoltage_18 1 "fault";
VAL_ 2449965062 Phase_V_overcurrent_18 1 "fault";
VAL_ 2449965062 Phase_W_overvoltage_18 1 "fault";
VAL_ 2449965062 Phase_W_undervoltage_18 1 "fault";
VAL_ 2449965062 Phase_W_overcurrent_18 1 "fault";
VAL_ 2449965062 DC_undervoltage_18 1 "fault";
VAL_ 2449965062 DC_overvoltage_18 1 "fault";
VAL_ 2449965062 MOSFET_overtemperature_18 1 "fault";
VAL_ 2449965062 Inductor_overtemperature_18 1 "fault";
VAL_ 2449965062 Keep_Alive_not_served_18 1 "fault";
VAL_ 2449965062 PLL_not_locked_18 1 "fault";
VAL_ 2449965062 NFO_18 1 "fault";
VAL_ 2449965062 Measurement_system_failure_18 1 "fault";
VAL_ 2449965062 EEPROM_failure_18 1 "fault";
VAL_ 2449965062 System_18 1 "fault";
VAL_ 2449965142 Current_U_High_18 1 "fault";
VAL_ 2449965142 Current_U_Low_18 1 "fault";
VAL_ 2449965142 Current_V_High_18 1 "fault";
VAL_ 2449965142 Current_V_Low_18 1 "fault";
VAL_ 2449965142 Current_W_High_18 1 "fault";
VAL_ 2449965142 Current_W_Low_18 1 "fault";
VAL_ 2449965142 Voltage_DC_18 1 "fault";
VAL_ 2449965142 Reboot_18 1 "fault";
VAL_ 2449965142 Unknown_18 1 "fault";
SIG_VALTYPE_ 2449965137 Current_U_18 : 1;
SIG_VALTYPE_ 2449965137 Current_V_18 : 1;
SIG_VALTYPE_ 2449965137 Current_W_18 : 1;
SIG_VALTYPE_ 2449965137 Voltage_U_18 : 1;
SIG_VALTYPE_ 2449965137 Voltage_V_18 : 1;
SIG_VALTYPE_ 2449965137 Voltage_W_18 : 1;
SIG_VALTYPE_ 2449965137 Voltage_DC_18 : 1;
SIG_VALTYPE_ 2449965138 Current_U_18 : 1;
SIG_VALTYPE_ 2449965138 Current_V_18 : 1;
SIG_VALTYPE_ 2449965138 Current_W_18 : 1;
SIG_VALTYPE_ 2449965138 Voltage_U_18 : 1;
SIG_VALTYPE_ 2449965138 Voltage_V_18 : 1;
SIG_VALTYPE_ 2449965138 Voltage_W_18 : 1;
SIG_VALTYPE_ 2449965138 Voltage_DC_18 : 1;
